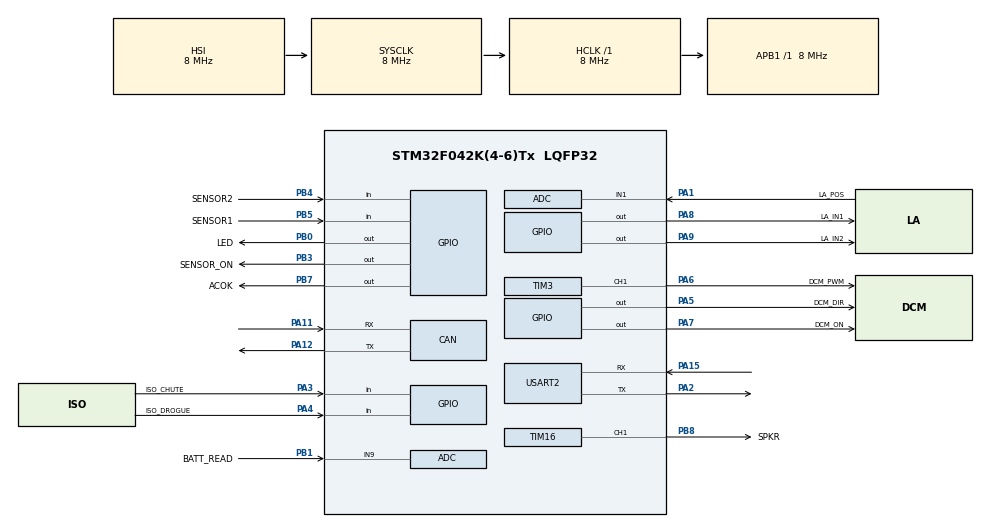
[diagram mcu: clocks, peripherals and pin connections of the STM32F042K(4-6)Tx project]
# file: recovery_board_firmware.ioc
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CAN.CalculateTimeQuantum=2000.0
Mcu.Family=STM32F0
Mcu.Name=STM32F042K(4-6)Tx
Mcu.Package=LQFP32
PA1.GPIO_Label=LA_POS
PA1.Mode=IN1
PA1.Signal=ADC_IN1
PA11.Mode=Master
PA11.Signal=CAN_RX
PA12.Mode=Master
PA12.Signal=CAN_TX
PA13.Mode=Serial_Wire
PA13.Signal=SYS_SWDIO
PA14.Mode=Serial_Wire
PA14.Signal=SYS_SWCLK
PA15.GPIO_ModeDefaultPP=GPIO_MODE_AF_PP
PA15.GPIO_PuPd=GPIO_NOPULL
PA15.GPIO_Speed=GPIO_SPEED_FREQ_HIGH
PA15.Mode=Asynchronous
PA15.Signal=USART2_RX
PA2.GPIO_ModeDefaultPP=GPIO_MODE_AF_PP
PA2.GPIO_PuPd=GPIO_NOPULL
PA2.GPIO_Speed=GPIO_SPEED_FREQ_HIGH
PA2.Mode=Asynchronous
PA2.Signal=USART2_TX
PA3.GPIO_Label=ISO_CHUTE
PA3.GPIO_Mode=GPIO_MODE_INPUT
PA3.GPIO_PuPd=GPIO_NOPULL
PA3.Signal=GPIO_Input
PA4.GPIO_Label=ISO_DROGUE
PA4.GPIO_Mode=GPIO_MODE_INPUT
PA4.GPIO_PuPd=GPIO_NOPULL
PA4.Signal=GPIO_Input
PA5.GPIO_Label=DCM_DIR
PA5.GPIO_ModeDefaultOutputPP=GPIO_MODE_OUTPUT_PP
PA5.GPIO_PuPd=GPIO_NOPULL
PA5.GPIO_Speed=GPIO_SPEED_FREQ_LOW
PA5.PinState=GPIO_PIN_RESET
PA5.Signal=GPIO_Output
PA6.GPIO_Label=DCM_PWM
PA6.Signal=S_TIM3_CH1
PA7.GPIO_Label=DCM_ON
PA7.GPIO_ModeDefaultOutputPP=GPIO_MODE_OUTPUT_PP
PA7.GPIO_PuPd=GPIO_NOPULL
PA7.GPIO_Speed=GPIO_SPEED_FREQ_LOW
PA7.PinState=GPIO_PIN_RESET
PA7.Signal=GPIO_Output
PA8.GPIO_Label=LA_IN1
PA8.GPIO_ModeDefaultOutputPP=GPIO_MODE_OUTPUT_PP
PA8.GPIO_PuPd=GPIO_NOPULL
PA8.GPIO_Speed=GPIO_SPEED_FREQ_LOW
PA8.PinState=GPIO_PIN_RESET
PA8.Signal=GPIO_Output
PA9.GPIO_FMA9=__NULL
PA9.GPIO_Label=LA_IN2
PA9.GPIO_ModeDefaultOutputPP=GPIO_MODE_OUTPUT_PP
PA9.GPIO_PuPd=GPIO_NOPULL
PA9.GPIO_Speed=GPIO_SPEED_FREQ_LOW
PA9.PinState=GPIO_PIN_RESET
PA9.Signal=GPIO_Output
PB0.GPIO_Label=LED
PB0.GPIO_ModeDefaultOutputPP=GPIO_MODE_OUTPUT_PP
PB0.GPIO_PuPd=GPIO_NOPULL
PB0.GPIO_Speed=GPIO_SPEED_FREQ_LOW
PB0.PinState=GPIO_PIN_RESET
PB0.Signal=GPIO_Output
PB1.GPIO_Label=BATT_READ
PB1.Mode=IN9
PB1.Signal=ADC_IN9
PB3.GPIO_Label=SENSOR_ON
PB3.GPIO_ModeDefaultOutputPP=GPIO_MODE_OUTPUT_PP
PB3.GPIO_PuPd=GPIO_NOPULL
PB3.GPIO_Speed=GPIO_SPEED_FREQ_LOW
PB3.PinState=GPIO_PIN_RESET
PB3.Signal=GPIO_Output
PB4.GPIO_Label=SENSOR2
PB4.Signal=GPIO_Input
PB5.GPIO_Label=SENSOR1
PB5.GPIO_Mode=GPIO_MODE_INPUT
PB5.GPIO_PuPd=GPIO_NOPULL
PB5.Signal=GPIO_Input
PB7.GPIO_FM7=__NULL
PB7.GPIO_Label=ACOK
PB7.GPIO_ModeDefaultOutputPP=GPIO_MODE_OUTPUT_PP
PB7.GPIO_PuPd=GPIO_NOPULL
PB7.GPIO_Speed=GPIO_SPEED_FREQ_LOW
PB7.PinState=GPIO_PIN_RESET
PB7.Signal=GPIO_Output
PB8.GPIO_Label=SPKR
PB8.Signal=S_TIM16_CH1
PF0-OSC_IN.Mode=HSE-External-Clock-Source
PF0-OSC_IN.Signal=RCC_OSC_IN
ProjectManager.HeapSize=0x200
ProjectManager.StackSize=0x400
ProjectManager.TargetToolchain=STM32CubeIDE
RCC.AHBFreq_Value=8000000
RCC.APB1Freq_Value=8000000
RCC.APB1TimFreq_Value=8000000
RCC.HCLKFreq_Value=8000000
RCC.SYSCLKFreq_VALUE=8000000
SH.S_TIM16_CH1.0=TIM16_CH1,PWM Generation1 CH1
SH.S_TIM3_CH1.0=TIM3_CH1,PWM Generation1 CH1
TIM16.Channel=TIM_CHANNEL_1
TIM16.Period=1000 - 1
TIM16.Prescaler=2-1
TIM3.Channel-PWM\ Generation1\ CH1=TIM_CHANNEL_1
USART2.VirtualMode-Asynchronous=VM_ASYNC
VP_TIM16_VS_ClockSourceINT.Mode=Enable_Timer
board=NUCLEO-F042K6

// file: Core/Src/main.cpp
/* USER CODE BEGIN Header */
/**
  ******************************************************************************
  * @file           : main.c
  * @brief          : Main program body
  ******************************************************************************
  * @attention
  *
  * <h2><center>&copy; Copyright (c) 2020 STMicroelectronics.
  * All rights reserved.</center></h2>
  *
  * This software component is licensed by ST under BSD 3-Clause license,
  * the "License"; You may not use this file except in compliance with the
  * License. You may obtain a copy of the License at:
  *                        opensource.org/licenses/BSD-3-Clause
  *
  ******************************************************************************
  */
/* USER CODE END Header */

#include "main.h"

/* USER CODE BEGIN Includes */
#include "recoveryFlight.h"
#include "recoveryUtils.h"
#include "checkupCode.h"
/* USER CODE END Includes */

ADC_HandleTypeDef hadc;

CAN_HandleTypeDef hcan;

TIM_HandleTypeDef htim3;
TIM_HandleTypeDef htim16;

UART_HandleTypeDef huart2;

void SystemClock_Config(void);
static void MX_GPIO_Init(void);
static void MX_USART2_UART_Init(void);
static void MX_CAN_Init(void);
static void MX_ADC_Init(void);
static void MX_TIM16_Init(void);
static void MX_TIM3_Init(void);
/* USER CODE BEGIN PFP */
static void flightInit(void);
/* USER CODE END PFP */

int main(void)
{

  /* MCU Configuration--------------------------------------------------------*/

  /* Reset of all peripherals, Initializes the Flash interface and the Systick. */
  HAL_Init();

  /* Configure the system clock */
  SystemClock_Config();

  /* Initialize all configured peripherals */
  MX_GPIO_Init();
  MX_USART2_UART_Init();
  MX_CAN_Init();
  MX_ADC_Init();
  MX_TIM16_Init();
  MX_TIM3_Init();
  /* USER CODE BEGIN 2 */

  flightInit();
  /* USER CODE END 2 */

  /* Infinite loop */
  /* USER CODE BEGIN WHILE */
  while (1)
  {
	  waitForAvionics(hadc);
    /* USER CODE END WHILE */

  }
}

void SystemClock_Config(void)
{
  RCC_OscInitTypeDef RCC_OscInitStruct = {0};
  RCC_ClkInitTypeDef RCC_ClkInitStruct = {0};

  /** Initializes the CPU, AHB and APB busses clocks
  */
  RCC_OscInitStruct.OscillatorType = RCC_OSCILLATORTYPE_HSI|RCC_OSCILLATORTYPE_HSI14;
  RCC_OscInitStruct.HSIState = RCC_HSI_ON;
  RCC_OscInitStruct.HSI14State = RCC_HSI14_ON;
  RCC_OscInitStruct.HSICalibrationValue = RCC_HSICALIBRATION_DEFAULT;
  RCC_OscInitStruct.HSI14CalibrationValue = 16;
  RCC_OscInitStruct.PLL.PLLState = RCC_PLL_NONE;
  if (HAL_RCC_OscConfig(&RCC_OscInitStruct) != HAL_OK)
  {
    Error_Handler();
  }
  /** Initializes the CPU, AHB and APB busses clocks
  */
  RCC_ClkInitStruct.ClockType = RCC_CLOCKTYPE_HCLK|RCC_CLOCKTYPE_SYSCLK
                              |RCC_CLOCKTYPE_PCLK1;
  RCC_ClkInitStruct.SYSCLKSource = RCC_SYSCLKSOURCE_HSI;
  RCC_ClkInitStruct.AHBCLKDivider = RCC_SYSCLK_DIV1;
  RCC_ClkInitStruct.APB1CLKDivider = RCC_HCLK_DIV1;

  if (HAL_RCC_ClockConfig(&RCC_ClkInitStruct, FLASH_LATENCY_0) != HAL_OK)
  {
    Error_Handler();
  }
}

static void MX_ADC_Init(void)
{

  ADC_ChannelConfTypeDef sConfig = {0};

  /** Configure the global features of the ADC (Clock, Resolution, Data Alignment and number of conversion)
  */
  hadc.Instance = ADC1;
  hadc.Init.ClockPrescaler = ADC_CLOCK_ASYNC_DIV1;
  hadc.Init.Resolution = ADC_RESOLUTION_12B;
  hadc.Init.DataAlign = ADC_DATAALIGN_RIGHT;
  hadc.Init.ScanConvMode = ADC_SCAN_DIRECTION_FORWARD;
  hadc.Init.EOCSelection = ADC_EOC_SINGLE_CONV;
  hadc.Init.LowPowerAutoWait = DISABLE;
  hadc.Init.LowPowerAutoPowerOff = DISABLE;
  hadc.Init.ContinuousConvMode = DISABLE;
  hadc.Init.DiscontinuousConvMode = DISABLE;
  hadc.Init.ExternalTrigConv = ADC_SOFTWARE_START;
  hadc.Init.ExternalTrigConvEdge = ADC_EXTERNALTRIGCONVEDGE_NONE;
  hadc.Init.DMAContinuousRequests = DISABLE;
  hadc.Init.Overrun = ADC_OVR_DATA_PRESERVED;
  if (HAL_ADC_Init(&hadc) != HAL_OK)
  {
    Error_Handler();
  }
  /** Configure for the selected ADC regular channel to be converted.
  */
  sConfig.Channel = ADC_CHANNEL_1;
  sConfig.Rank = ADC_RANK_CHANNEL_NUMBER;
  sConfig.SamplingTime = ADC_SAMPLETIME_1CYCLE_5;
  if (HAL_ADC_ConfigChannel(&hadc, &sConfig) != HAL_OK)
  {
    Error_Handler();
  }
  /** Configure for the selected ADC regular channel to be converted.
  */
  sConfig.Channel = ADC_CHANNEL_9;
  if (HAL_ADC_ConfigChannel(&hadc, &sConfig) != HAL_OK)
  {
    Error_Handler();
  }

}

static void MX_CAN_Init(void)
{

  hcan.Instance = CAN;
  hcan.Init.Prescaler = 16;
  hcan.Init.Mode = CAN_MODE_NORMAL;
  hcan.Init.SyncJumpWidth = CAN_SJW_1TQ;
  hcan.Init.TimeSeg1 = CAN_BS1_1TQ;
  hcan.Init.TimeSeg2 = CAN_BS2_1TQ;
  hcan.Init.TimeTriggeredMode = DISABLE;
  hcan.Init.AutoBusOff = DISABLE;
  hcan.Init.AutoWakeUp = DISABLE;
  hcan.Init.AutoRetransmission = DISABLE;
  hcan.Init.ReceiveFifoLocked = DISABLE;
  hcan.Init.TransmitFifoPriority = DISABLE;
  if (HAL_CAN_Init(&hcan) != HAL_OK)
  {
    Error_Handler();
  }

}

static void MX_TIM3_Init(void)
{

  TIM_MasterConfigTypeDef sMasterConfig = {0};
  TIM_OC_InitTypeDef sConfigOC = {0};

  htim3.Instance = TIM3;
  htim3.Init.Prescaler = 13;
  htim3.Init.CounterMode = TIM_COUNTERMODE_UP;
  htim3.Init.Period = 142;
  htim3.Init.ClockDivision = TIM_CLOCKDIVISION_DIV1;
  htim3.Init.AutoReloadPreload = TIM_AUTORELOAD_PRELOAD_DISABLE;
  if (HAL_TIM_PWM_Init(&htim3) != HAL_OK)
  {
    Error_Handler();
  }
  sMasterConfig.MasterOutputTrigger = TIM_TRGO_RESET;
  sMasterConfig.MasterSlaveMode = TIM_MASTERSLAVEMODE_DISABLE;
  if (HAL_TIMEx_MasterConfigSynchronization(&htim3, &sMasterConfig) != HAL_OK)
  {
    Error_Handler();
  }
  sConfigOC.OCMode = TIM_OCMODE_PWM1;
  sConfigOC.Pulse = 0;
  sConfigOC.OCPolarity = TIM_OCPOLARITY_HIGH;
  sConfigOC.OCFastMode = TIM_OCFAST_DISABLE;
  if (HAL_TIM_PWM_ConfigChannel(&htim3, &sConfigOC, TIM_CHANNEL_1) != HAL_OK)
  {
    Error_Handler();
  }
  HAL_TIM_MspPostInit(&htim3);

}

static void MX_TIM16_Init(void)
{

  TIM_OC_InitTypeDef sConfigOC = {0};
  TIM_BreakDeadTimeConfigTypeDef sBreakDeadTimeConfig = {0};

  htim16.Instance = TIM16;
  htim16.Init.Prescaler = 1;
  htim16.Init.CounterMode = TIM_COUNTERMODE_UP;
  htim16.Init.Period = 999;
  htim16.Init.ClockDivision = TIM_CLOCKDIVISION_DIV1;
  htim16.Init.RepetitionCounter = 0;
  htim16.Init.AutoReloadPreload = TIM_AUTORELOAD_PRELOAD_DISABLE;
  if (HAL_TIM_Base_Init(&htim16) != HAL_OK)
  {
    Error_Handler();
  }
  if (HAL_TIM_PWM_Init(&htim16) != HAL_OK)
  {
    Error_Handler();
  }
  sConfigOC.OCMode = TIM_OCMODE_PWM1;
  sConfigOC.Pulse = 0;
  sConfigOC.OCPolarity = TIM_OCPOLARITY_HIGH;
  sConfigOC.OCNPolarity = TIM_OCNPOLARITY_HIGH;
  sConfigOC.OCFastMode = TIM_OCFAST_DISABLE;
  sConfigOC.OCIdleState = TIM_OCIDLESTATE_RESET;
  sConfigOC.OCNIdleState = TIM_OCNIDLESTATE_RESET;
  if (HAL_TIM_PWM_ConfigChannel(&htim16, &sConfigOC, TIM_CHANNEL_1) != HAL_OK)
  {
    Error_Handler();
  }
  sBreakDeadTimeConfig.OffStateRunMode = TIM_OSSR_DISABLE;
  sBreakDeadTimeConfig.OffStateIDLEMode = TIM_OSSI_DISABLE;
  sBreakDeadTimeConfig.LockLevel = TIM_LOCKLEVEL_OFF;
  sBreakDeadTimeConfig.DeadTime = 0;
  sBreakDeadTimeConfig.BreakState = TIM_BREAK_DISABLE;
  sBreakDeadTimeConfig.BreakPolarity = TIM_BREAKPOLARITY_HIGH;
  sBreakDeadTimeConfig.AutomaticOutput = TIM_AUTOMATICOUTPUT_DISABLE;
  if (HAL_TIMEx_ConfigBreakDeadTime(&htim16, &sBreakDeadTimeConfig) != HAL_OK)
  {
    Error_Handler();
  }
  HAL_TIM_MspPostInit(&htim16);

}

static void MX_USART2_UART_Init(void)
{

  huart2.Instance = USART2;
  huart2.Init.BaudRate = 38400;
  huart2.Init.WordLength = UART_WORDLENGTH_8B;
  huart2.Init.StopBits = UART_STOPBITS_1;
  huart2.Init.Parity = UART_PARITY_NONE;
  huart2.Init.Mode = UART_MODE_TX_RX;
  huart2.Init.HwFlowCtl = UART_HWCONTROL_NONE;
  huart2.Init.OverSampling = UART_OVERSAMPLING_16;
  huart2.Init.OneBitSampling = UART_ONE_BIT_SAMPLE_DISABLE;
  huart2.AdvancedInit.AdvFeatureInit = UART_ADVFEATURE_NO_INIT;
  if (HAL_UART_Init(&huart2) != HAL_OK)
  {
    Error_Handler();
  }

}

static void MX_GPIO_Init(void)
{
  GPIO_InitTypeDef GPIO_InitStruct = {0};

  /* GPIO Ports Clock Enable */
  __HAL_RCC_GPIOF_CLK_ENABLE();
  __HAL_RCC_GPIOA_CLK_ENABLE();
  __HAL_RCC_GPIOB_CLK_ENABLE();

  /*Configure GPIO pin Output Level */
  HAL_GPIO_WritePin(GPIOA, DCM_DIR_Pin|DCM_ON_Pin|LA_IN1_Pin|LA_IN2_Pin, GPIO_PIN_RESET);

  /*Configure GPIO pin Output Level */
  HAL_GPIO_WritePin(GPIOB, LED_Pin|SENSOR_ON_Pin|ACOK_Pin, GPIO_PIN_RESET);

  /*Configure GPIO pins : ISO_CHUTE_Pin ISO_DROGUE_Pin */
  GPIO_InitStruct.Pin = ISO_CHUTE_Pin|ISO_DROGUE_Pin;
  GPIO_InitStruct.Mode = GPIO_MODE_INPUT;
  GPIO_InitStruct.Pull = GPIO_NOPULL;
  HAL_GPIO_Init(GPIOA, &GPIO_InitStruct);

  /*Configure GPIO pins : DCM_DIR_Pin DCM_ON_Pin LA_IN1_Pin LA_IN2_Pin */
  GPIO_InitStruct.Pin = DCM_DIR_Pin|DCM_ON_Pin|LA_IN1_Pin|LA_IN2_Pin;
  GPIO_InitStruct.Mode = GPIO_MODE_OUTPUT_PP;
  GPIO_InitStruct.Pull = GPIO_NOPULL;
  GPIO_InitStruct.Speed = GPIO_SPEED_FREQ_LOW;
  HAL_GPIO_Init(GPIOA, &GPIO_InitStruct);

  /*Configure GPIO pins : LED_Pin SENSOR_ON_Pin ACOK_Pin */
  GPIO_InitStruct.Pin = LED_Pin|SENSOR_ON_Pin|ACOK_Pin;
  GPIO_InitStruct.Mode = GPIO_MODE_OUTPUT_PP;
  GPIO_InitStruct.Pull = GPIO_NOPULL;
  GPIO_InitStruct.Speed = GPIO_SPEED_FREQ_LOW;
  HAL_GPIO_Init(GPIOB, &GPIO_InitStruct);

  /*Configure GPIO pins : SENSOR2_Pin SENSOR1_Pin */
  GPIO_InitStruct.Pin = SENSOR2_Pin|SENSOR1_Pin;
  GPIO_InitStruct.Mode = GPIO_MODE_INPUT;
  GPIO_InitStruct.Pull = GPIO_NOPULL;
  HAL_GPIO_Init(GPIOB, &GPIO_InitStruct);

}

/* USER CODE BEGIN 4 */
void flightInit(void){
	// start the input capture of PWM
	TIM2_PWM_InputInit();
}
/* USER CODE END 4 */

void Error_Handler(void)
{
}

/************************ (C) COPYRIGHT STMicroelectronics *****END OF FILE****/
